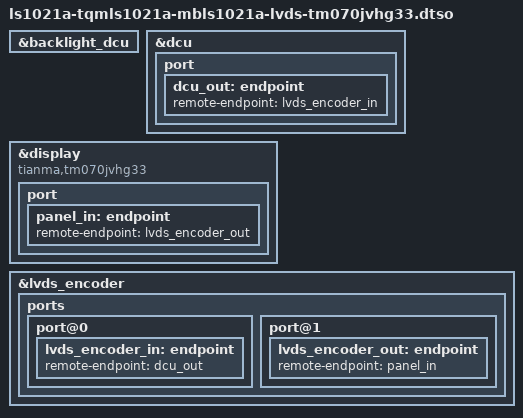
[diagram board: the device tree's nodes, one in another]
// SPDX-License-Identifier: (GPL-2.0-or-later OR X11)
/*
 * Copyright 2018-2023 TQ-Systems GmbH <linux@ew.tq-group.com>,
 * D-82229 Seefeld, Germany.
 * Author: Alexander Stein

 */

/dts-v1/;
/plugin/;

#include <dt-bindings/gpio/gpio.h>

&backlight_dcu {
	status = "okay";
};

&dcu {
	status = "okay";

	port {

		dcu_out: endpoint {
			remote-endpoint = <&lvds_encoder_in>;
		};
	};
};

&display {
	compatible = "tianma,tm070jvhg33";
	status = "okay";

	port {
		panel_in: endpoint {
			remote-endpoint = <&lvds_encoder_out>;
		};
	};
};

&lvds_encoder {
	status = "okay";

	ports {
		port@0 {
			lvds_encoder_in: endpoint {
				remote-endpoint = <&dcu_out>;
			};
		};

		port@1 {
			lvds_encoder_out: endpoint {
				remote-endpoint = <&panel_in>;
			};
		};
	};
};
